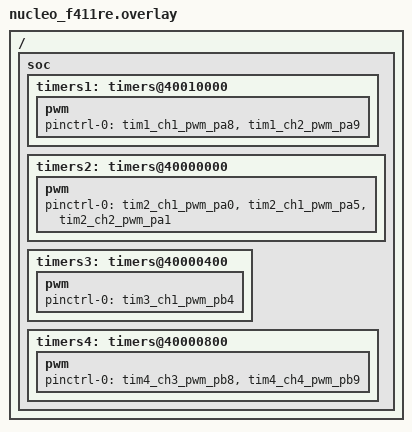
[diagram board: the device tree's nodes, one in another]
/ {
    soc {
        timers1: timers@40010000 {
            status = "okay";
        
            pwm {
                status = "okay";
                pinctrl-0 = <&tim1_ch1_pwm_pa8 &tim1_ch2_pwm_pa9>;
            };
        };

        timers2: timers@40000000 {
            status = "okay";
        
            pwm {
                status = "okay";
                pinctrl-0 = <&tim2_ch1_pwm_pa0 &tim2_ch1_pwm_pa5 &tim2_ch2_pwm_pa1>;
            };
        };

        timers3: timers@40000400 {
            status = "okay";
        
            pwm {
                status = "okay";
                pinctrl-0 = <&tim3_ch1_pwm_pb4>;
            };
        };

        timers4: timers@40000800 {
            status = "okay";
        
            pwm {
                status = "okay";
                pinctrl-0 = <&tim4_ch3_pwm_pb8 &tim4_ch4_pwm_pb9>;
            };
        };
    };
};
